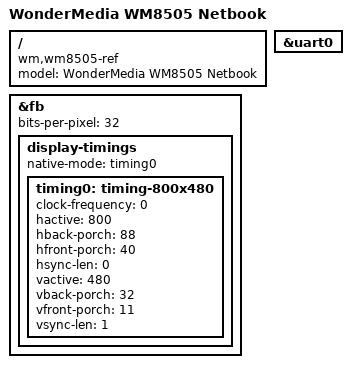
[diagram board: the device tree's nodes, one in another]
// SPDX-License-Identifier: GPL-2.0-or-later
/*
 * wm8505-ref.dts - Device tree file for WonderMedia WM8505 reference netbook
 *
 * Copyright (C) 2012 Tony Prisk <linux@prisktech.co.nz>
 */

/dts-v1/;

#include "wm8505.dtsi"

/ {
	model = "WonderMedia WM8505 Netbook";
	compatible = "wm,wm8505-ref", "wm,wm8505";
};

&fb {
	bits-per-pixel = <32>;

	display-timings {
		native-mode = <&timing0>;

		timing0: timing-800x480 {
			clock-frequency = <0>; /* Unused but required */
			hactive = <800>;
			hback-porch = <88>;
			hfront-porch = <40>;
			hsync-len = <0>;
			vactive = <480>;
			vback-porch = <32>;
			vfront-porch = <11>;
			vsync-len = <1>;
		};
	};
};

&uart0 {
	status = "okay";
};
